# AT32F403Axx register map
Vendor: Keil; Series: AT32F403A; File version: 1.0
CPU: CM4 r0p1, little endian, no MPU, FPU, 4 interrupt priority bits
Registers are 32-bit, read-write, reset 0x0 unless marked. A register's access mark holds for its fields unless they carry their own. Offsets are from the block's base; [hi:lo] are bit positions; {n}, {i} and the like mark numbered series.

## SDIO1 — Secure digital input/output interface
Base 0x40018000
Same registers: SDIO2 0x40023400
0x00 POWER — Bits 1:0 = PWRCTRL: Power supply control bits
  [1:0] PWRCTRL
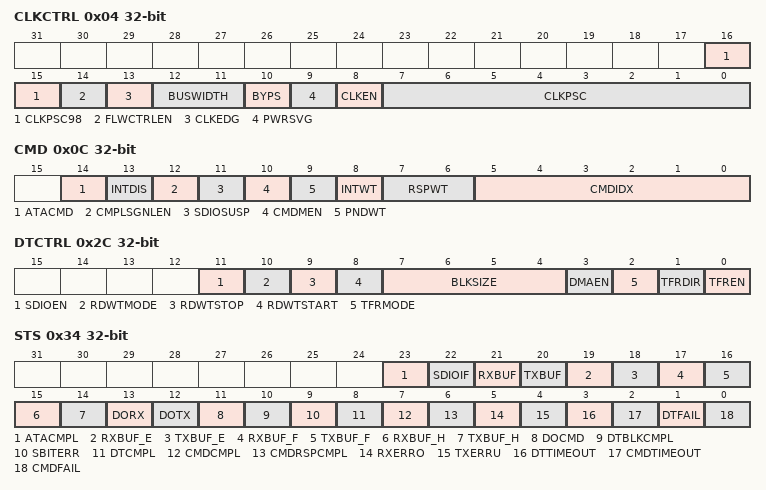
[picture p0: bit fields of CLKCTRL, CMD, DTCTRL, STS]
0x04 CLKCTRL — SDI clock control register (SDIO_CLKCTRL)
  [16:15] CLKPSC98 — Clock divide factor bit9 and bit8
  [14] FLWCTRLEN — HW Flow Control enable
  [13] CLKEDG — SDIO_CK dephasing selection bit
  [12:11] BUSWIDTH — Wide bus mode enable bit
  [10] BYPS — Clock divider bypass enable bit
  [9] PWRSVG — Power saving configuration bit
  [8] CLKEN — Clock enable bit
  [7:0] CLKPSC — Clock divide factor
0x08 ARG — Bits 31:0 = : Command argument
  [31:0] ARG — Command argument
0x0C CMD — SDIO command register (SDIO_CMD)
  [14] ATACMD — CE_ATACMD
  [13] INTDIS — nIEN
  [12] CMPLSGNLEN — ENCMDcompl
  [11] SDIOSUSP — SDIOSuspend
  [10] CMDMEN — CPSMEN
  [9] PNDWT — WAITPEND
  [8] INTWT — WAITINT
  [7:6] RSPWT — WAITRESP
  [5:0] CMDIDX
0x10 RSPCMD ro — SDIO command register
  [5:0] RSPCMD
0x14 RSP1 ro — Bits 31:0 = CARDSTATUS1
  [31:0] CARDSTS1 — CARDSTATUS1
{0x10+4i} RSP{i} ro (i=2..4) — Bits 31:0 = CARDSTATUS{i}
  [31:0] CARDSTS2 — CARDSTATUS{i}
0x24 DTTMR — Bits 31:0 = DATATIME: Data timeout period
  [31:0] TIMEOUT — Data timeout period
0x28 DTLEN — Bits 24:0 = DATALENGTH: Data length value
  [24:0] DTLEN — Data length value
0x2C DTCTRL — SDIO data control register (SDIO_DCTRL)
  [11] SDIOEN
  [10] RDWTMODE — RWMOD
  [9] RDWTSTOP — PWSTOP
  [8] RDWTSTART — PWSTART
  [7:4] BLKSIZE — DBLOCKSIZE
  [3] DMAEN
  [2] TFRMODE — DTMODE
  [1] TFRDIR — DTDIR
  [0] TFREN — DTEN
0x30 DTCNTR ro — Bits 24:0 = DATACOUNT: Data count value
  [24:0] CNT — Data count value
0x34 STS ro — SDIO status register (SDIO_STA)
  [23] ATACMPL — CEATAEND
  [22] SDIOIF — SDIOIT
  [21] RXBUF — RXDAVL
  [20] TXBUF — TXDAVL
  [19] RXBUF_E — RXFIFOE
  [18] TXBUF_E — TXFIFOE
  [17] RXBUF_F — RXFIFOF
  [16] TXBUF_F — TXFIFOF
  [15] RXBUF_H — RXFIFOHF
  [14] TXBUF_H — TXFIFOHE
  [13] DORX — RXACT
  [12] DOTX — TXACT
  [11] DOCMD — CMDACT
  [10] DTBLKCMPL — DBCKEND
  [9] SBITERR — STBITERR
  [8] DTCMPL — DATAEND
  [7] CMDCMPL — CMDSENT
  [6] CMDRSPCMPL — CMDREND
  [5] RXERRO — RXOVERR
  [4] TXERRU — TXUNDERR
  [3] DTTIMEOUT — DTIMEOUT
  [2] CMDTIMEOUT — CTIMEOUT
  [1] DTFAIL — DCRCFAIL
  [0] CMDFAIL — CCRCFAIL
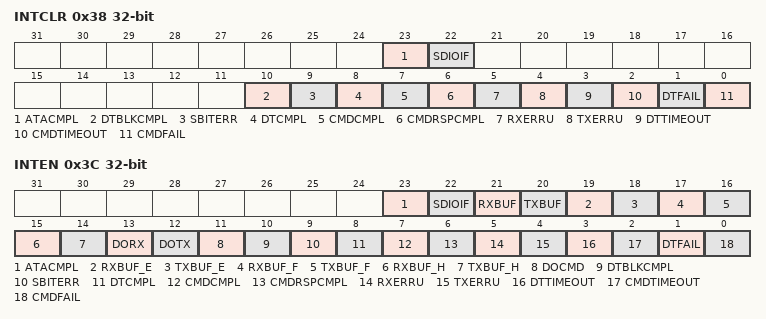
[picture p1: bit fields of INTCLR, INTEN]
0x38 INTCLR — SDIO interrupt clear register (SDIO_INTCLR)
  [23] ATACMPL — CEATAENDC
  [22] SDIOIF — SDIOITC
  [10] DTBLKCMPL — DBCKENDC
  [9] SBITERR — STBITERRC
  [8] DTCMPL — DATAENDC
  [7] CMDCMPL — CMDSENTC
  [6] CMDRSPCMPL — CMDRENDC
  [5] RXERRU — RXOVERRC
  [4] TXERRU — TXUNDERRC
  [3] DTTIMEOUT — DTIMEOUTC
  [2] CMDTIMEOUT — CTIMEOUTC
  [1] DTFAIL — DCRCFAILC
  [0] CMDFAIL — CCRCFAILC
0x3C INTEN — SDIO mask register (SDIO_MASK)
  [23] ATACMPL — CEATENDIE
  [22] SDIOIF — SDIOITIE
  [21] RXBUF — RXDAVLIE
  [20] TXBUF — TXDAVLIE
  [19] RXBUF_E — RXFIFOEIE
  [18] TXBUF_E — TXFIFOEIE
  [17] RXBUF_F — RXFIFOFIE
  [16] TXBUF_F — TXFIFOFIE
  [15] RXBUF_H — RXFIFOHFIE
  [14] TXBUF_H — TXFIFOHEIE
  [13] DORX — RXACTIE
  [12] DOTX — TXACTIE
  [11] DOCMD — CMDACTIE
  [10] DTBLKCMPL — DBACKENDIE
  [9] SBITERR — STBITERRIE
  [8] DTCMPL — DATAENDIE
  [7] CMDCMPL — CMDSENTIE
  [6] CMDRSPCMPL — CMDRENDIE
  [5] RXERRU — RXOVERRIE
  [4] TXERRU — TXUNDERRIE
  [3] DTTIMEOUT — DTIMEOUTIE
  [2] CMDTIMEOUT — CTIMEOUTIE
  [1] DTFAIL — DCRCFAILIE
  [0] CMDFAIL — CCRCFAILIE
0x48 BUFCNTR ro — Bits 23:0 = FIFOCOUNT: Remaining number of words to be written to or read from the FIFO
  [23:0] CNT — FIF0COUNT
0x80 BUF — bits 31:0 = FIFOData: Receive and transmit FIFO data
  [31:0] DT — FIFOData

## RTC — Real time clock
Base 0x40002800
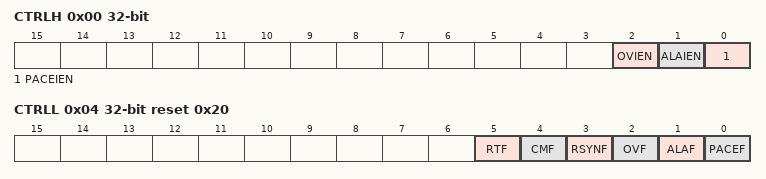
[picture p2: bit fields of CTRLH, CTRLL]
0x00 CTRLH — RTC Control Register High
  [2] OVIEN — Overflow interrupt Enable
  [1] ALAIEN — Alarm interrupt Enable
  [0] PACEIEN — Second interrupt Enable
0x04 CTRLL reset 0x20 — RTC Control Register Low
  [5] RTF ro — RTC operation OFF
  [4] CMF — Configuration Flag
  [3] RSYNF — Registers Synchronized Flag
  [2] OVF — Overflow Flag
  [1] ALAF — Alarm Flag
  [0] PACEF — Second Flag
0x08 DIVH wo — RTC Prescaler Load Register High
  [3:0] DIV
0x0C DIVL wo reset 0x8000 — RTC Prescaler Load Register Low
  [15:0] DIV — RTC Prescaler Divider Register Low
0x10 DIVCNTH — RTC Prescaler Divider Register High
  [3:0] DIVCNT — RTC prescaler divider register high
0x14 DIVCNTL reset 0x8000 — RTC Prescaler Divider Register Low
  [15:0] DIVCNT — RTC prescaler divider register Low
0x18 CNTH — RTC Counter Register High
  [15:0] CNT — RTC counter register high
0x1C CNTL — RTC Counter Register Low
  [15:0] CNT — RTC counter register Low
0x20 ALAH wo reset 0xFFFF — RTC Alarm Register High
  [15:0] ALA — RTC alarm register high
0x24 ALAL wo reset 0xFFFF — RTC Alarm Register Low
  [15:0] ALA — RTC alarm register low

## Notices in the file
Copyright (C) 2012-2014 ARM Limited. All rights reserved.
Purpose: System Viewer Description (SVD) Example (Schema Version 1.1)
This is a description of a none-existent and incomplete device
for demonstration purposes only.
Redistribution and use in source and binary forms, with or without
modification, are permitted provided that the following conditions are met:
- Redistributions of source code must retain the above copyright
notice, this list of conditions and the following disclaimer.
- Redistributions in binary form must reproduce the above copyright
notice, this list of conditions and the following disclaimer in the
documentation and/or other materials provided with the distribution.
- Neither the name of ARM nor the names of its contributors may be used
to endorse or promote products derived from this software without
specific prior written permission.
THIS SOFTWARE IS PROVIDED BY THE COPYRIGHT HOLDERS AND CONTRIBUTORS "AS IS"
AND ANY EXPRESS OR IMPLIED WARRANTIES, INCLUDING, BUT NOT LIMITED TO, THE
IMPLIED WARRANTIES OF MERCHANTABILITY AND FITNESS FOR A PARTICULAR PURPOSE
ARE DISCLAIMED. IN NO EVENT SHALL COPYRIGHT HOLDERS AND CONTRIBUTORS BE
LIABLE FOR ANY DIRECT, INDIRECT, INCIDENTAL, SPECIAL, EXEMPLARY, OR
CONSEQUENTIAL DAMAGES (INCLUDING, BUT NOT LIMITED TO, PROCUREMENT OF
SUBSTITUTE GOODS OR SERVICES; LOSS OF USE, DATA, OR PROFITS; OR BUSINESS
INTERRUPTION) HOWEVER CAUSED AND ON ANY THEORY OF LIABILITY, WHETHER IN
CONTRACT, STRICT LIABILITY, OR TORT (INCLUDING NEGLIGENCE OR OTHERWISE)
ARISING IN ANY WAY OUT OF THE USE OF THIS SOFTWARE, EVEN IF ADVISED OF THE
POSSIBILITY OF SUCH DAMAGE.
